AUTOSAR XML (schema 00048)
package /ComponentTypes
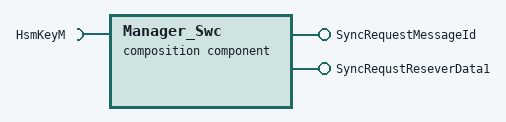
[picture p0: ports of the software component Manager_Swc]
  composition sw component type Manager_Swc
    provide port SyncRequestMessageId: nonqueued-sender-com-spec{data-element=SyncRequestMessageId, init-value=17}, provided-interface=SyncRequestMessageId
    provide port SyncRequstReseverData1: nonqueued-sender-com-spec{data-element=SyncRequstReseverData1, init-value=7 x 0}, provided-interface=SyncRequstReseverData1
    require port HsmKeyM: required-com-specs=[SetCmacKey, SetAes128Key, GetCmacKeyState, GetCmacKey, GetAes128Key], required-interface=HsmKeyM
    11 x component:
      EOL: type=EOL
      Power: type=Power
      Upgrade: type=Upgrade
      Vconfig: type=Vconfig
      SOCManager: type=SOCManager
      DCM_Server: type=DCM_Server
      Can_Server: type=Can_Server
      DidDataProcess: type=DidDataProcess
      SocDtcProcess: type=SocDtcProcess
      CConfig: type=CConfig
      SecOc_Server: type=SecOc_Server
    connect Power.Power_Voltage -> DCM_Server.Power_Voltage
    connect Vconfig.VConfig_GetKindConfig -> EOL.VConfig_GetKindConfig
    connect Vconfig.VConfig_GetKindConfig -> Can_Server.VConfig_GetKindConfig
    connect DidDataProcess.ECUlevelNetworkConfigurationDataIdentifier -> Vconfig.ECUlevelNetworkConfigurationDataIdentifier
    connect Vconfig.VconfigResponseFlag -> DidDataProcess.VconfigResponseFlag
    connect SOCManager.ppSR_SocManager -> Power.rpSR_SocManager
    connect Power.ppSR_Power_Out -> SOCManager.rpSR_Power_Out
    connect SocDtcProcess.IPCSocReportDtcStatus -> DidDataProcess.IPCSocReportDtcStatus
    connect Vconfig -> DCM_Server
    connect Power.ppSR_Power_Out -> Can_Server.tiSR_Power_Out
    connect Power.ppSR_WakeupReason -> Can_Server.rpSR_WakeupReason
    delegate SecOc_Server.SyncRequestMessageId <-> outer port SyncRequestMessageId
    delegate SecOc_Server.SyncRequstReseverData1 <-> outer port SyncRequstReseverData1
    delegate SecOc_Server.HsmKeyM <-> outer port HsmKeyM
    connect DidDataProcess.tiSR_VIN -> SecOc_Server.tiSR_VIN
    connect Upgrade.ppSR_Upgrade_System_Recovery -> SOCManager.rpSR_Upgrade_System_Recovery
    connect DidDataProcess.VconfigRequestUpdateFlag -> Vconfig.VconfigRequestUpdateFlag
    connect DidDataProcess.CconfigRequestUpdateFlag -> CConfig.CconfigRequestUpdateFlag
    connect SocDtcProcess.pPSR_DiagMonitorReInitFlag -> SecOc_Server.piDiagMonitorReInitFlag
    connect SocDtcProcess.pPSR_DiagMonitorReInitFlag -> Can_Server.Can_Server_piDiagMonitorReInitFlag
